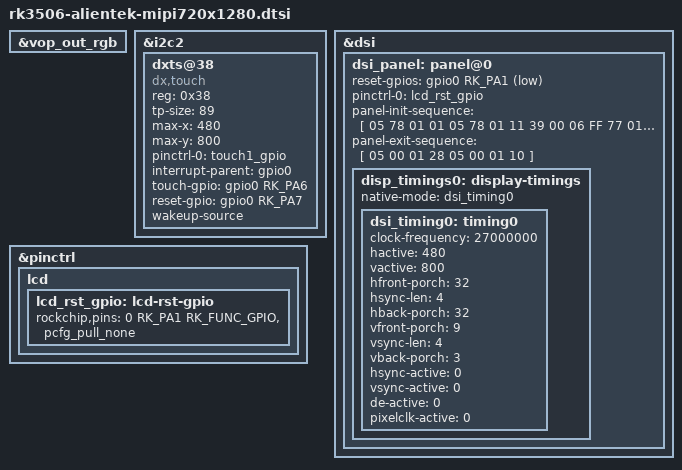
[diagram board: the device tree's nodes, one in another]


#define D310T9362V1     1
#define D350T1013V1     0
#define D240C2501V1     0	
#define D280C2518V0     0	
#define D300T9307V1     0
#define BOE446GC9503    0
#define D200C2409V0     0
#define D500C9366V1     0 
#define D395C930UV0     0
#define D500C930SV0     0   //5" g5 7201280
#define D050C2523V0     0   //5" g6 7201280
#define D050C2521V0     0   //5" 1024600
#define D070C2529V0     0    //7" 1024600
#define D060C2522V0     0   //6" 720 1440
#define D320C2403V1     0
#define D200N2415V0     0



&vop_out_rgb {
        /delete-property/ remote-endpoint;
};




&i2c2 {

	dxts@38 {

               compatible = "dx,touch";
               reg = <0x38>;
               tp-size = <89>;
               max-x = <480>;
               max-y = <800>;
               pinctrl-names = "default";
               pinctrl-0 = <&touch1_gpio>;
	       interrupt-parent = <&gpio0>;
               touch-gpio = <&gpio0 RK_PA6 IRQ_TYPE_LEVEL_LOW>;
               reset-gpio = <&gpio0 RK_PA7 GPIO_ACTIVE_HIGH>;
                wakeup-source;
                //touchscreen-inverted-x;
                //touchscreen-swapped-x-y;
                status = "okay";
        };

	/delete-node/ gt1x;
};



// ************************************************************************************************************************************************
// 3.1寸大显 D310T9362V1
// 480x800
// ************************************************************************************************************************************************
	#if(D310T9362V1)
	

&dsi {
	status = "okay";
//	rockchip,lane-rate = <1000>;
        dsi_panel: panel@0 {
        	reset-gpios = <&gpio0 RK_PA1 GPIO_ACTIVE_LOW>;
                pinctrl-names = "default";
                pinctrl-0 = <&lcd_rst_gpio>;

		panel-init-sequence = [
			// init code
			05 78 01 01
			05 78 01 11
			39 00 06 FF 77 01 00 00 11
			15 00 02 D1 11
			15 00 02 55 B0 // 80 90 b0
			39 00 06 FF 77 01 00 00 10
			39 00 03 C0 63 00
			39 00 03 C1 09 02
			39 00 03 C2 37 08
			15 00 02 C7 00 // x-dir rotate 0:0x00,rotate 180:0x04
			15 00 02 CC 38
			39 00 11 B0 00 11 19 0C 10 06 07 0A 09 22 04 10 0E 28 30 1C
			39 00 11 B1 00 12 19 0D 10 04 06 07 08 23 04 12 11 28 30 1C
			39 00 06 FF 77 01 00 00 11 // enable  bk fun of  command 2  BK1
			15 00 02 B0 4D
			15 00 02 B1 60 // 0x56  0x4a  0x5b
			15 00 02 B2 07
			15 00 02 B3 80
			15 00 02 B5 47
			15 00 02 B7 8A
			15 00 02 B8 21
			15 00 02 C1 78
			15 00 02 C2 78
			15 64 02 D0 88
			39 00 04 E0 00 00 02
			39 00 0C E1 01 A0 03 A0 02 A0 04 A0 00 44 44
			39 00 0D E2 00 00 00 00 00 00 00 00 00 00 00 00
			39 00 05 E3 00 00 33 33
			39 00 03 E4 44 44
			39 00 11 E5 01 26 A0 A0 03 28 A0 A0 05 2A A0 A0 07 2C A0 A0
			39 00 05 E6 00 00 33 33
			39 00 03 E7 44 44
			39 00 11 E8 02 26 A0 A0 04 28 A0 A0 06 2A A0 A0 08 2C A0 A0
			39 00 08 EB 00 01 E4 E4 44 00 40
			39 00 11 ED FF F7 65 4F 0B A1 CF FF FF FC 1A B0 F4 56 7F FF
		  //  39 00 06 FF 77 01 00 00 12  //BIST
          //  15 00 02 D1 81 
		  //  15 00 02 D2 07
			39 00 06 FF 77 01 00 00 00
			15 00 02 36 00 //U&D  Y-DIR rotate 0:0x00,rotate 180:0x10
			05 78 01 11           
			05 14 01 29		
		];

		panel-exit-sequence = [
			05 00 01 28
			05 00 01 10
		];

                disp_timings0: display-timings {
                        native-mode = <&dsi_timing0>;
                        dsi_timing0: timing0 {
 				clock-frequency = <27000000>;
				hactive = <480>;   	
				vactive = <800>;   	 
				hfront-porch = <32>;  
				hsync-len = <4>;   	 
				hback-porch = <32>;  
				vfront-porch = <9>;  
				vsync-len = <4>;     
				vback-porch = <3>;   
				hsync-active = <0>;
				vsync-active = <0>;
				de-active = <0>;
				pixelclk-active = <0>;
                        };
                };

        };
};
#endif






// ************************************************************************************************************************************************
// 3.5寸大显 D350T1013V1
// 480x800
// ************************************************************************************************************************************************
	#if(D350T1013V1)
	
&dsi {
	status = "okay";
//	rockchip,lane-rate = <1000>;
        dsi_panel: panel@0 {
        	reset-gpios = <&gpio0 RK_PA1 GPIO_ACTIVE_LOW>;
                pinctrl-names = "default";
                pinctrl-0 = <&lcd_rst_gpio>;

		panel-init-sequence = [
			// init code
			15 00 02 B0 5D
			15 00 02 B1 72 // VCOM
			15 00 02 B2 82
			15 00 02 B3 80
			15 00 02 B5 42
			15 00 02 B7 85
			15 00 02 B8 20
			15 00 02 C1 78
			15 00 02 C2 78
			15 64 02 D0 88
			39 00 04 E0 00 00 02
			39 00 0C E1 04 A0 06 A0 05 A0 07 A0 00 44 44
			39 00 0D E2 00 00 33 33 01 A0 00 00 01 A0 00 00
			39 00 05 E3 00 00 33 33
			39 00 03 E4 44 44
			39 00 11 E5 0C 30 A0 A0 0E 32 A0 A0 08 2C A0 A0 0A 2E A0 A0
			39 00 05 E6 00 00 33 33
			39 00 03 E7 44 44
			39 00 11 E8 0D 31 A0 A0 0F 33 A0 A0 09 2D A0 A0 0B 2F A0 A0
			39 00 08 EB 00 01 E4 E4 44 88 00
			39 00 11 ED FF F5 47 6F 0B A1 A2 BF FB 2A 1A B0 F6 74 5F FF
			39 00 07 FF 08 08 08 40 3F 64
			39 00 06 FF 77 01 00 00 13
			39 00 03 E8 00 0E
			39 00 06 FF 77 01 00 00 00
			05 78 01 11    
			39 00 06 FF 77 01 00 00 13
			39 14 03 E8 00 0C   
			39 00 03 E8 00 00  
          //  39 00 06 FF 77 01 00 00 12  //BIST
          //  15 00 D1 81 
		  //  15 00 D2 07
			39 00 06 FF 77 01 00 00 00 
			05 14 01 29		
		];

		panel-exit-sequence = [
			05 00 01 28
			05 00 01 10
		];

                disp_timings0: display-timings {
                        native-mode = <&dsi_timing0>;
                        dsi_timing0: timing0 {
 				clock-frequency = <27000000>;
				hactive = <480>;   	
				vactive = <800>;   	 
				hfront-porch = <32>;  
				hsync-len = <4>;   	 
				hback-porch = <32>;  
				vfront-porch = <9>;  
				vsync-len = <4>;     
				vback-porch = <3>;   
				hsync-active = <0>;
				vsync-active = <0>;
				de-active = <0>;
				pixelclk-active = <0>;
                        };
                };

        };
};
#endif


// ************************************************************************************************************************************************
// 2.4寸大显 D240C2501V1
// 480x640
// ************************************************************************************************************************************************
 
	#if(D240C2501V1)
&dsi {
	status = "okay";
//	rockchip,lane-rate = <1000>;
        dsi_panel: panel@0 {
        	reset-gpios = <&gpio0 RK_PA1 GPIO_ACTIVE_LOW>;
                pinctrl-names = "default";
                pinctrl-0 = <&lcd_rst_gpio>;

		panel-init-sequence = [
			// init code
			05 78 01 01
			39 00 06 FF 77 01 00 00 13
			15 00 02 EF 08
			39 00 06 FF 77 01 00 00 10
			39 00 03 C0 4F 00
			39 00 03 C1 10 0C
			39 00 03 C2 37 04
			15 00 02 C7 00 // x-dir rotate 0:0x00,rotate 180:0x04
			15 00 02 CC 10
			39 00 11 B0 00 0B 13 0D 10 07 02 08 07 1F 04 11 0F 28 2F 1F
			39 00 11 B1 00 0C 13 0C 10 05 02 08 08 1E 05 13 11 27 30 1F
			39 00 06 FF 77 01 00 00 11 // enable  bk fun of  command 2  BK1
			15 00 02 B0 4A //VOP
			15 00 02 B1 4A // VCOM
			15 00 02 B2 87 //VGH
			15 00 02 B3 80
			15 00 02 B5 45 //VGL
			15 00 02 B7 85
			15 00 02 B8 20
			15 00 02 C1 78
			15 00 02 C2 78
			15 64 02 D0 88
			39 00 04 E0 00 00 02
			39 00 0C E1 04 B0 06 B0 05 B0 05 B0 00 44 44
			39 00 0D E2 20 20 44 44 96 A0 00 00 96 A0 00 00
			39 00 05 E3 00 00 22 22
			39 00 03 E4 44 44
			39 00 11 E5 0C 90 B0 A0 0E 92 B0 A0 08 8C B0 A0 0A 8E B0 A0
			39 00 05 E6 00 00 22 22
			39 00 03 E7 44 44
			39 00 11 E8 0D 91 B0 A0 0F 93 B0 A0 09 8D B0 A0 0B 8F B0 A0
			39 00 03 E9 36 44
			39 00 08 EB 00 00 E4 E4 44 00 40
			39 00 11 ED C1 A2 BF 0F 67 45 FF FF FF FF 54 76 F0 FB 2A 1C
			39 00 07 EF 10 0D 04 08 3F 1F
			39 00 06 FF 77 01 00 00 13
		    39 00 03 E8 00 0E
			39 00 06 FF 77 01 00 00 00
	        05 78 01 11
			39 00 06 FF 77 01 00 00 13
		    39 14 03 E8 00 0C
		    39 14 03 E8 00 00
			39 00 06 FF 77 01 00 00 00
			15 00 02 36 00 //U&D  Y-DIR rotate 0:0x00,rotate 180:0x10          
			05 14 01 29		
		];

		panel-exit-sequence = [
			05 00 01 28
			05 00 01 10
		];

                disp_timings0: display-timings {
                        native-mode = <&dsi_timing0>;
                        dsi_timing0: timing0 {
				clock-frequency = <21000000>;
				hactive = <480>;   	
				vactive = <640>;   	 
				hfront-porch = <10>;  
				hsync-len = <2>;   	 
				hback-porch = <10>;  
				vfront-porch = <30>;  
				vsync-len = <2>;     
				vback-porch = <30>;   
				hsync-active = <0>;
				vsync-active = <0>;
				de-active = <0>;
				pixelclk-active = <0>;
                        };
                };

        };
};
#endif



// ************************************************************************************************************************************************
// 2.8寸大显 D280C2518V0
// 480x640
// ************************************************************************************************************************************************
 	#if(D280C2518V0)
	
&dsi {
	status = "okay";
//	rockchip,lane-rate = <1000>;
        dsi_panel: panel@0 {
        	reset-gpios = <&gpio0 RK_PA1 GPIO_ACTIVE_LOW>;
                pinctrl-names = "default";
                pinctrl-0 = <&lcd_rst_gpio>;

		panel-init-sequence = [
			// init code
39 00 06 FF 77 01 00 00 13
15 00 02 EF 08
39 00 06 FF 77 01 00 00 10
39 00 03 C0 4F 00
39 00 03 C1 10 02
39 00 03 C2 00 02
15 00 02 CC 10
39 00 11 B0 00 10 17 0D 11 06 05 08 07 1F 04 11 0E 29 30 1F
39 00 11 B1 00 0D 14 0E 11 06 04 08 08 20 05 13 13 26 30 1F
39 00 06 FF 77 01 00 00 11
15 00 02 B0 69
15 00 02 B1 71
15 00 02 B2 82
15 00 02 B3 80
15 00 02 B5 42
15 00 02 B7 85
15 00 02 B8 20
15 00 02 C0 09
15 00 02 C1 78
15 00 02 C2 78
15 00 02 D0 88
15 00 02 EE 42
39 00 04 E0 00 00 02
39 00 0c E1 04 A0 06 A0 05 A0 07 A0 00 44 44
39 00 0d E2 00 00 00 00 00 00 00 00 00 00 00 00
39 00 05 E3 00 00 22 22
39 00 03 E4 44 44
39 00 11 E5 0c 90 A0 A0 0E 92 A0 A0 08 8C A0 A0 0A 8E A0 A0
39 00 05 E6 00 00 22 22
39 00 03 E7 44 44
39 00 11 E8 0D 91 A0 A0 0F 93 A0 A0 09 8D A0 A0 0B 8F A0 A0
//39 00 03 E9 36 00
39 00 08 EB 00 00 E4 E4 44 00 40
39 00 11 ED FF F5 47 6F 0B A1 AB FF FF BA 1A B0 F6 74 5F FF
39 00 07 EF 08 08 08 40 3F 64
39 00 06 FF 77 01 00 00 00
39 00 06 FF 77 01 00 00 13
39 00 03 E6 16 7C
39 00 03 E8 00 0E
39 00 06 FF 77 01 00 00 00
15 78 02 11 00
39 00 06 FF 77 01 00 00 13
39 14 03 E8 00 0C
39 00 03 E8 00 00
//bist
//39 00 06 FF 77 01 00 00 12
//15 00 02 D1 81
//15 00 02 D2 07
39 00 06 FF 77 01 00 00 00
15 00 02 3A 70
05 14 01 29
		];

		panel-exit-sequence = [
			05 00 01 28
			05 00 01 10
		];

                disp_timings0: display-timings {
                        native-mode = <&dsi_timing0>;
                        dsi_timing0: timing0 {
				clock-frequency = <21000000>;
				hactive = <480>;   	
				vactive = <640>;   	 
				hfront-porch = <10>;  
				hsync-len = <2>;   	 
				hback-porch = <10>;  
				vfront-porch = <30>;  
				vsync-len = <2>;     
				vback-porch = <30>;   
				hsync-active = <0>;
				vsync-active = <0>;
				de-active = <0>;
				pixelclk-active = <0>;
                        };
                };

        };
};
#endif




// ************************************************************************************************************************************************
// 3.0寸大显 D300T9307V1
// 480x854
// ************************************************************************************************************************************************
	#if(D300T9307V1)
	
&dsi {
	status = "okay";
        dsi_panel: panel@0 {
        	reset-gpios = <&gpio0 RK_PA1 GPIO_ACTIVE_LOW>;
                pinctrl-names = "default";
                pinctrl-0 = <&lcd_rst_gpio>;

		panel-init-sequence = [
			// init code
			15 00 02 B0 5D
			15 00 02 B1 72 // VCOM
			15 00 02 B2 82
			15 00 02 B3 80
			15 00 02 B5 42
			15 00 02 B7 85
		05 78 01 01
			39 00 06 FF 77 01 00 00 13
			15 00 02 EF 08
			39 00 06 FF 77 01 00 00 10
			39 00 03 C0 E9 03
			39 00 03 C1 12 0C
			39 00 03 C2 27 0A
			15 00 02 CC 10
			39 00 11 B0 00 23 2A 0A 0E 03 12 06 06 2A 00 10 0F 2D 34 1F
			39 00 11 B1 00 24 2B 0F 12 07 15 0A 0A 2B 08 13 10 2D 33 1F
			39 00 06 FF 77 01 00 00 11 // enable  bk fun of  command 2  BK1
			15 00 02 B0 5D
			15 00 02 B1 74 // VCOM
			15 00 02 B2 84
			15 00 02 B3 80
			15 00 02 B5 45
			15 00 02 B7 85
			15 00 02 B8 33
			15 00 02 C1 78
			15 00 02 C2 78
			15 64 02 D0 88
			39 00 04 E0 00 00 02
            39 00 0C E1 06 A0 08 A0 05 A0 07 A0 00 44 44 
            39 00 0D E2 30 30 44 44 6E A0 00 00 6E A0 00 00 
            39 00 05 E3 00 00 33 33 
            39 00 03 E4 44 44 
            39 00 11 E5 0D 69 0A A0 0F 6B 0A A0 09 65 0A A0 0B 67 0A A0 
            39 00 05 E6 00 00 33 33 
            39 00 03 E7 44 44 
            39 00 11 E8 0C 68 0A A0 0E 6A 0A A0 08 64 0A A0 0A 66 0A A0 
            39 00 03 E9 36 00 
            39 00 08 EB 00 01 E4 E4 44 88 40 
            39 00 11 ED FF 45 67 FA 01 2B CF FF FF FC B2 10 AF 76 54 FF  
            39 00 07 EF 10 0D 04 08 3F 1F 
            //BIST
            //39 00 06 FF 77 01 00 00 12
            //15 00 02 D1 81
             //15 00 02 D2 07
			39 00 06 FF 77 01 00 00 00
			15 00 02 36 00 
			15 00 02 3A 70
			05 78 01 11           
			05 14 01 29		
		];

		panel-exit-sequence = [
			05 00 01 28
			05 00 01 10
		];

                disp_timings0: display-timings {
                        native-mode = <&dsi_timing0>;
                        dsi_timing0: timing0 {
 				clock-frequency = <27000000>;
				hactive = <480>;   	
				vactive = <854>;   	 
				hfront-porch = <7>;  
				hsync-len = <2>;   	 
				hback-porch = <11>;  
				vfront-porch = <22>;  
				vsync-len = <2>;     
				vback-porch = <12>;   
				hsync-active = <0>;
				vsync-active = <0>;
				de-active = <0>;
				pixelclk-active = <0>;
                        };
                };

        };
};
#endif







&pinctrl {
        lcd {
                lcd_rst_gpio: lcd-rst-gpio {
                        rockchip,pins = <0 RK_PA1 RK_FUNC_GPIO &pcfg_pull_none>;
                };
        };
};

